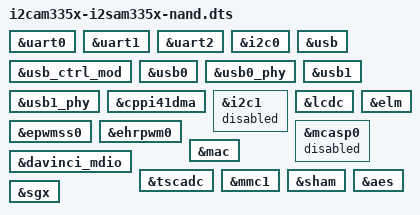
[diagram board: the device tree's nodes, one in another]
/*
 * Copyright (C) 2012 Texas Instruments Incorporated - http://www.ti.com/
 *
 * This program is free software; you can redistribute it and/or modify
 * it under the terms of the GNU General Public License version 2 as
 * published by the Free Software Foundation.
 */
/dts-v1/;

#include "i2s-am335x-nand.dtsi"
#include "i2cam335x-i2sam335x-nand.dtsi"

&uart0 {
	status = "okay";
};

&uart1 {
	status = "okay";
};

&uart2 {
	status = "okay";
};

&i2c0 {
	status = "okay";
};

&usb {
	status = "okay";
};

&usb_ctrl_mod {
	status = "okay";
};

&usb0 {
	status = "okay";
};

&usb0_phy {
	status = "okay";
};

&usb1 {
	status = "okay";
};

&usb1_phy {
	status = "okay";
};

&cppi41dma  {
	status = "okay";
};

&i2c1 {
	status = "disabled";
};

&lcdc {
	status = "okay";
};

&elm {
	status = "okay";
};

&epwmss0 {
	status = "okay";
};

&ehrpwm0 {
	status = "okay";
};

&mcasp0 {
	status = "disabled";
};

&mac {
	status = "okay";
};

&davinci_mdio {
	status = "okay";
};

&tscadc {
	status = "okay";
};

&mmc1 {
	status = "okay";
};

&sham {
	status = "okay";
};

&aes {
	status = "okay";
};

&sgx {
	status = "okay";
};
